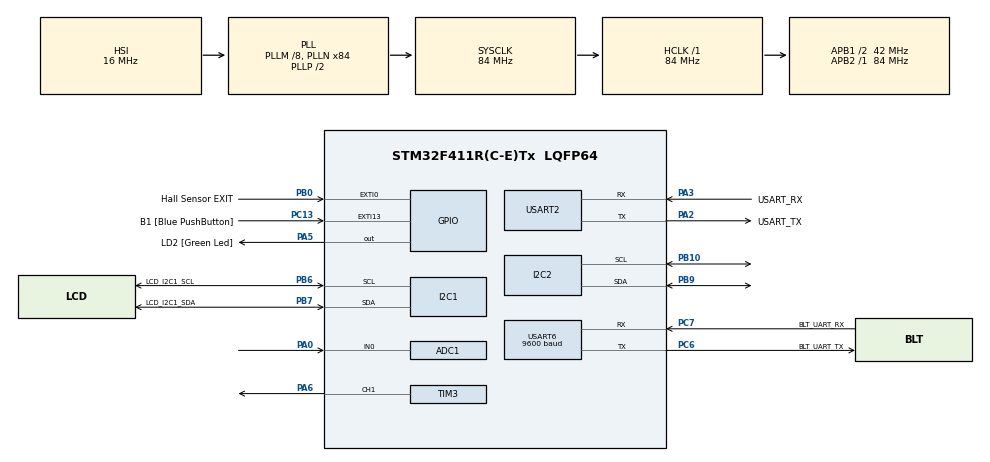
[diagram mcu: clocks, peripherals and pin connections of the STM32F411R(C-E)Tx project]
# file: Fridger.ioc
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ADC1.Channel-0\#ChannelRegularConversion=ADC_CHANNEL_0
ADC1.ContinuousConvMode=ENABLE
ADC1.DMAContinuousRequests=DISABLE
ADC1.ExternalTrigConv=ADC_SOFTWARE_START
ADC1.NbrOfConversionFlag=1
ADC1.Rank-0\#ChannelRegularConversion=1
ADC1.SamplingTime-0\#ChannelRegularConversion=ADC_SAMPLETIME_3CYCLES
ADC1.master=1
FREERTOS.Tasks01=defaultTask,24,128,StartDefaultTask,As weak,NULL,Dynamic,NULL,NULL;MySensorTask,8,1024,sensorTask,As weak,NULL,Dynamic,NULL,NULL;MyCommTask,8,512,commTask,As weak,NULL,Dynamic,NULL,NULL
Mcu.Family=STM32F4
Mcu.Name=STM32F411R(C-E)Tx
Mcu.Package=LQFP64
NVIC.EXTI0_IRQn=true\:5\:0\:false\:false\:true\:true\:true\:true\:true
NVIC.EXTI15_10_IRQn=true\:5\:0\:false\:false\:true\:true\:true\:true\:true
NVIC.I2C2_ER_IRQn=true\:5\:0\:false\:false\:true\:true\:true\:true\:true
NVIC.I2C2_EV_IRQn=true\:5\:0\:false\:false\:true\:true\:true\:true\:true
NVIC.PriorityGroup=NVIC_PRIORITYGROUP_4
NVIC.TIM1_UP_TIM10_IRQn=true\:15\:0\:false\:false\:true\:false\:false\:true\:true
NVIC.TimeBase=TIM1_UP_TIM10_IRQn
NVIC.TimeBaseIP=TIM10
NVIC.USART6_IRQn=true\:5\:0\:false\:false\:true\:true\:true\:true\:true
PA0-WKUP.Signal=ADCx_IN0
PA13.GPIO_Label=TMS
PA13.Mode=Serial_Wire
PA13.Signal=SYS_JTMS-SWDIO
PA14.GPIO_Label=TCK
PA14.Mode=Serial_Wire
PA14.Signal=SYS_JTCK-SWCLK
PA2.GPIO_Label=USART_TX
PA2.Mode=Asynchronous
PA2.Signal=USART2_TX
PA3.GPIO_Label=USART_RX
PA3.Mode=Asynchronous
PA3.Signal=USART2_RX
PA5.GPIO_Label=LD2 [Green Led]
PA5.Signal=GPIO_Output
PA6.Signal=S_TIM3_CH1
PB0.GPIO_Label=Hall Sensor EXIT
PB0.GPIO_ModeDefaultEXTI=GPIO_MODE_IT_RISING_FALLING
PB0.Signal=GPXTI0
PB10.GPIO_Pu=GPIO_PULLUP
PB10.Mode=I2C
PB10.Signal=I2C2_SCL
PB3.GPIO_Label=SWO
PB3.Signal=SYS_JTDO-SWO
PB6.GPIO_Label=LCD_I2C1_SCL
PB6.Mode=I2C
PB6.Signal=I2C1_SCL
PB7.GPIO_Label=LCD_I2C1_SDA
PB7.Mode=I2C
PB7.Signal=I2C1_SDA
PB9.GPIO_Pu=GPIO_PULLUP
PB9.Mode=I2C
PB9.Signal=I2C2_SDA
PC13-ANTI_TAMP.GPIO_Label=B1 [Blue PushButton]
PC13-ANTI_TAMP.GPIO_ModeDefaultEXTI=GPIO_MODE_IT_FALLING
PC13-ANTI_TAMP.Signal=GPXTI13
PC14-OSC32_IN.Mode=LSE-External-Oscillator
PC14-OSC32_IN.Signal=RCC_OSC32_IN
PC15-OSC32_OUT.Mode=LSE-External-Oscillator
PC15-OSC32_OUT.Signal=RCC_OSC32_OUT
PC6.GPIO_Label=BLT_UART_TX
PC6.Mode=Asynchronous
PC6.Signal=USART6_TX
PC7.GPIO_Label=BLT_UART_RX
PC7.Mode=Asynchronous
PC7.Signal=USART6_RX
PH0\ -\ OSC_IN.Mode=HSE-External-Clock-Source
PH0\ -\ OSC_IN.Signal=RCC_OSC_IN
PH1\ -\ OSC_OUT.Mode=HSE-External-Clock-Source
PH1\ -\ OSC_OUT.Signal=RCC_OSC_OUT
ProjectManager.HeapSize=0x200
ProjectManager.StackSize=0x400
ProjectManager.TargetToolchain=CMake
RCC.48MHZClocksFreq_Value=42000000
RCC.AHBFreq_Value=84000000
RCC.APB1CLKDivider=RCC_HCLK_DIV2
RCC.APB1Freq_Value=42000000
RCC.APB1TimFreq_Value=84000000
RCC.APB2Freq_Value=84000000
RCC.APB2TimFreq_Value=84000000
RCC.CortexFreq_Value=84000000
RCC.FLatency-AdvancedSettings=FLASH_LATENCY_2
RCC.HCLKFreq_Value=84000000
RCC.HSE_VALUE=8000000
RCC.HSI_VALUE=16000000
RCC.PLLM=8
RCC.PLLN=84
RCC.SYSCLKFreq_VALUE=84000000
RCC.SYSCLKSource=RCC_SYSCLKSOURCE_PLLCLK
RCC.VCOOutputFreq_Value=168000000
SH.ADCx_IN0.0=ADC1_IN0,IN0
SH.S_TIM3_CH1.0=TIM3_CH1,PWM Generation1 CH1
TIM3.Channel-PWM\ Generation1\ CH1=TIM_CHANNEL_1
TIM4.Period=4999
TIM4.Prescaler=8399
USART2.VirtualMode=VM_ASYNC
USART6.BaudRate=9600
USART6.VirtualMode=VM_ASYNC
VP_FREERTOS_VS_CMSIS_V2.Mode=CMSIS_V2
VP_SYS_VS_tim10.Mode=TIM10
VP_TIM4_VS_ClockSourceINT.Mode=Internal
board=NUCLEO-F411RE

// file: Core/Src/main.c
/* USER CODE BEGIN Header */
/**
  ******************************************************************************
  * @file           : main.c
  * @brief          : Main program body
  ******************************************************************************
  * @attention
  *
  * Copyright (c) 2026 STMicroelectronics.
  * All rights reserved.
  *
  * This software is licensed under terms that can be found in the LICENSE file
  * in the root directory of this software component.
  * If no LICENSE file comes with this software, it is provided AS-IS.
  *
  ******************************************************************************
  */
/* USER CODE END Header */
#include "main.h"
#include "cmsis_os.h"
#include "adc.h"
#include "i2c.h"
#include "tim.h"
#include "usart.h"
#include "gpio.h"

void SystemClock_Config(void);
void MX_FREERTOS_Init(void);

int main(void)
{

  /* MCU Configuration--------------------------------------------------------*/

  /* Reset of all peripherals, Initializes the Flash interface and the Systick. */
  HAL_Init();

  /* Configure the system clock */
  SystemClock_Config();

  /* Initialize all configured peripherals */
  MX_GPIO_Init();
  MX_ADC1_Init();
  MX_USART2_UART_Init();
  MX_USART6_UART_Init();
  MX_I2C1_Init();
  MX_TIM3_Init();
  MX_TIM4_Init();
  MX_I2C2_Init();

  /* Init scheduler */
  osKernelInitialize();  /* Call init function for freertos objects (in cmsis_os2.c) */
  MX_FREERTOS_Init();

  /* Start scheduler */
  osKernelStart();

  /* We should never get here as control is now taken by the scheduler */

  /* Infinite loop */
  /* USER CODE BEGIN WHILE */
  while (1)
  {
    HAL_GPIO_TogglePin(GPIOA, GPIO_PIN_5);
    HAL_Delay(500);
    /* USER CODE END WHILE */

    /* USER CODE BEGIN 3 */
  }
  osKernelInitialize();
  MX_FREERTOS_Init();
  osKernelStart();
  /* USER CODE END 3 */
}

void SystemClock_Config(void)
{
  RCC_OscInitTypeDef RCC_OscInitStruct = {0};
  RCC_ClkInitTypeDef RCC_ClkInitStruct = {0};

  /** Configure the main internal regulator output voltage
  */
  __HAL_RCC_PWR_CLK_ENABLE();
  __HAL_PWR_VOLTAGESCALING_CONFIG(PWR_REGULATOR_VOLTAGE_SCALE1);

  /** Initializes the RCC Oscillators according to the specified parameters
  * in the RCC_OscInitTypeDef structure.
  */
  RCC_OscInitStruct.OscillatorType = RCC_OSCILLATORTYPE_HSI;
  RCC_OscInitStruct.HSIState = RCC_HSI_ON;
  RCC_OscInitStruct.HSICalibrationValue = RCC_HSICALIBRATION_DEFAULT;
  RCC_OscInitStruct.PLL.PLLState = RCC_PLL_ON;
  RCC_OscInitStruct.PLL.PLLSource = RCC_PLLSOURCE_HSI;
  RCC_OscInitStruct.PLL.PLLM = 8;
  RCC_OscInitStruct.PLL.PLLN = 84;
  RCC_OscInitStruct.PLL.PLLP = RCC_PLLP_DIV2;
  RCC_OscInitStruct.PLL.PLLQ = 4;
  if (HAL_RCC_OscConfig(&RCC_OscInitStruct) != HAL_OK)
  {
    Error_Handler();
  }

  /** Initializes the CPU, AHB and APB buses clocks
  */
  RCC_ClkInitStruct.ClockType = RCC_CLOCKTYPE_HCLK|RCC_CLOCKTYPE_SYSCLK
                              |RCC_CLOCKTYPE_PCLK1|RCC_CLOCKTYPE_PCLK2;
  RCC_ClkInitStruct.SYSCLKSource = RCC_SYSCLKSOURCE_PLLCLK;
  RCC_ClkInitStruct.AHBCLKDivider = RCC_SYSCLK_DIV1;
  RCC_ClkInitStruct.APB1CLKDivider = RCC_HCLK_DIV2;
  RCC_ClkInitStruct.APB2CLKDivider = RCC_HCLK_DIV1;

  if (HAL_RCC_ClockConfig(&RCC_ClkInitStruct, FLASH_LATENCY_2) != HAL_OK)
  {
    Error_Handler();
  }
}

void HAL_TIM_PeriodElapsedCallback(TIM_HandleTypeDef *htim)
{
  if (htim->Instance == TIM10)
  {
    HAL_IncTick();
  }
}

void Error_Handler(void)
{
  __disable_irq();
  while (1)
  {
  }
}

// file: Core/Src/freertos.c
/* USER CODE BEGIN Header */
/**
  ******************************************************************************
  * File Name          : freertos.c
  * Description        : Code for freertos applications
  ******************************************************************************
  * @attention
  *
  * Copyright (c) 2026 STMicroelectronics.
  * All rights reserved.
  *
  * This software is licensed under terms that can be found in the LICENSE file
  * in the root directory of this software component.
  * If no LICENSE file comes with this software, it is provided AS-IS.
  *
  ******************************************************************************
  */
/* USER CODE END Header */

#include "FreeRTOS.h"
#include "task.h"
#include "main.h"
#include "cmsis_os.h"

/* Definitions for defaultTask */
osThreadId_t defaultTaskHandle;
const osThreadAttr_t defaultTask_attributes = {
  .name = "defaultTask",
  .stack_size = 128 * 4,
  .priority = (osPriority_t) osPriorityNormal,
};
/* Definitions for MySensorTask */
osThreadId_t MySensorTaskHandle;
const osThreadAttr_t MySensorTask_attributes = {
  .name = "MySensorTask",
  .stack_size = 1024 * 4,
  .priority = (osPriority_t) osPriorityLow,
};
/* Definitions for MyCommTask */
osThreadId_t MyCommTaskHandle;
const osThreadAttr_t MyCommTask_attributes = {
  .name = "MyCommTask",
  .stack_size = 512 * 4,
  .priority = (osPriority_t) osPriorityLow,
};

void StartDefaultTask(void *argument);
void sensorTask(void *argument);
void commTask(void *argument);

void MX_FREERTOS_Init(void); /* (MISRA C 2004 rule 8.1) */

void MX_FREERTOS_Init(void) {

  /* Create the thread(s) */
  /* creation of defaultTask */
  defaultTaskHandle = osThreadNew(StartDefaultTask, NULL, &defaultTask_attributes);

  /* creation of MySensorTask */
  MySensorTaskHandle = osThreadNew(sensorTask, NULL, &MySensorTask_attributes);

  /* creation of MyCommTask */
  MyCommTaskHandle = osThreadNew(commTask, NULL, &MyCommTask_attributes);

}

__weak void StartDefaultTask(void *argument)
{
  for(;;)
  {
    osDelay(1);
  }
}

__weak void sensorTask(void *argument)
{
  for(;;)
  {
    osDelay(1);
  }
}

__weak void commTask(void *argument)
{
  for(;;)
  {
    osDelay(1);
  }
}
